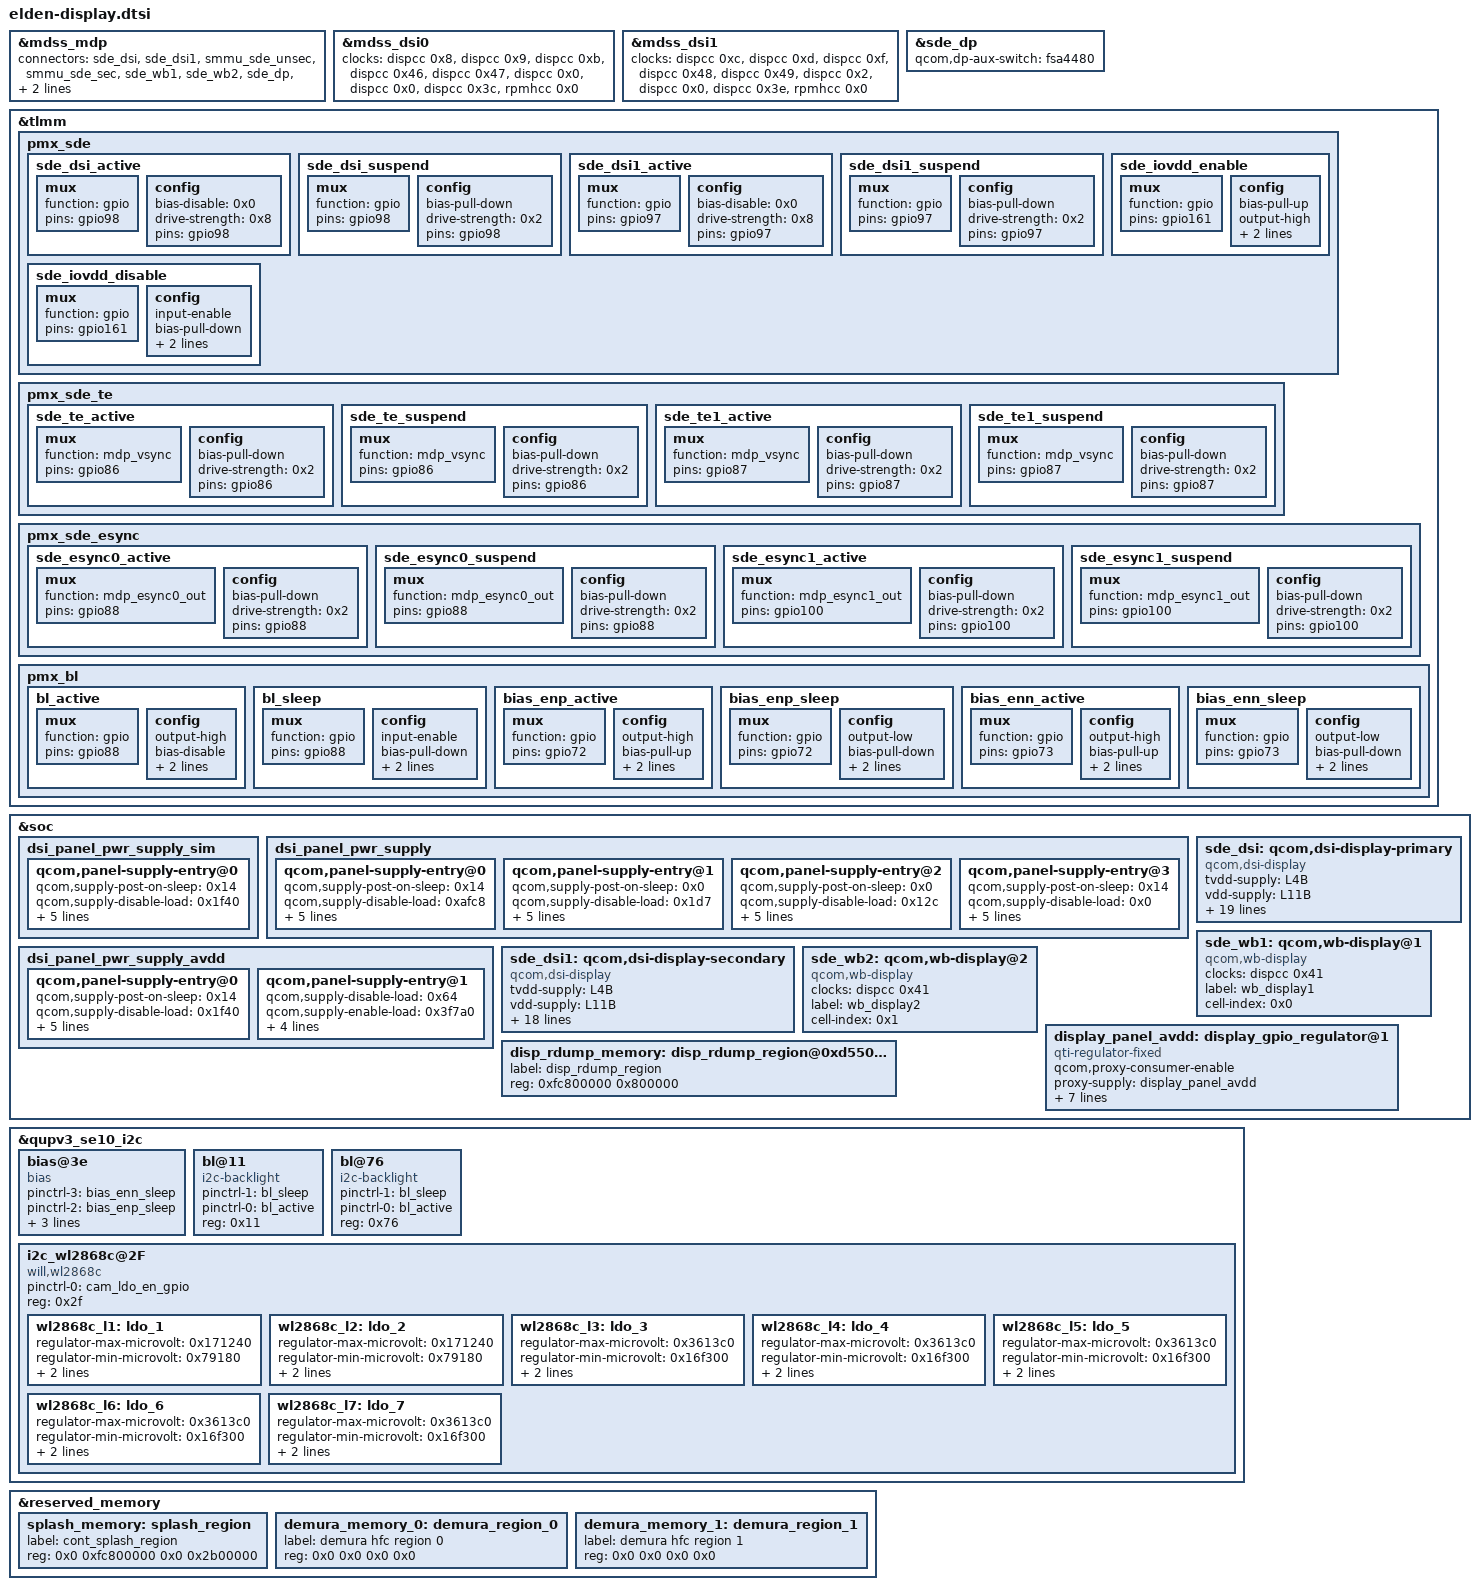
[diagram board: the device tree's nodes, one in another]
// SPDX-License-Identifier: GPL-2.0-only

#include "display/display/sun-sde.dtsi"

&mdss_mdp {
	connectors = <&sde_dsi &sde_dsi1 &smmu_sde_unsec &smmu_sde_sec &sde_wb1 &sde_wb2 &sde_dp &sde_cesta>;
	qcom,sde-max-bw-high-kbps = <0x1b2e020>;
	/delete-property/ qcom,sde-ctl-hyp-off;
	/delete-property/ qcom,sde-ctl-hyp-size;
};

&mdss_dsi0 {
	clocks = <&dispcc 0x8 &dispcc 0x9 &dispcc 0xb &dispcc 0x46 &dispcc 0x47 &dispcc 0x0 &dispcc 0x0 &dispcc 0x3c &rpmhcc 0x0>;
};

&mdss_dsi1 {
	clocks = <&dispcc 0xc &dispcc 0xd &dispcc 0xf &dispcc 0x48 &dispcc 0x49 &dispcc 0x2 &dispcc 0x0 &dispcc 0x3e &rpmhcc 0x0>;
};

&sde_dp {
	qcom,dp-aux-switch = <&fsa4480>;
};

#include "display/lenovo/elden-reference-panels.dtsi"
#include "display/lenovo/panel/dsi-panel-elden-nt36523-csot-3k-dsc-video.dtsi"
#include "display/lenovo/panel/dsi-panel-elden-nt36523-csot-dsc-video.dtsi"

&tlmm {

	pmx_sde: pmx_sde {

		sde_dsi_active: sde_dsi_active {

			mux {
				function = "gpio";
				pins = "gpio98";
			};

			config {
				bias-disable = <0x0>;
				drive-strength = <0x8>;
				pins = "gpio98";
			};
		};

		sde_dsi_suspend: sde_dsi_suspend {

			mux {
				function = "gpio";
				pins = "gpio98";
			};

			config {
				bias-pull-down;
				drive-strength = <0x2>;
				pins = "gpio98";
			};
		};

		sde_dsi1_active: sde_dsi1_active {

			mux {
				function = "gpio";
				pins = "gpio97";
			};

			config {
				bias-disable = <0x0>;
				drive-strength = <0x8>;
				pins = "gpio97";
			};
		};

		sde_dsi1_suspend: sde_dsi1_suspend {

			mux {
				function = "gpio";
				pins = "gpio97";
			};

			config {
				bias-pull-down;
				drive-strength = <0x2>;
				pins = "gpio97";
			};
		};

		sde_iovdd_enable: sde_iovdd_enable {

			mux {
				function = "gpio";
				pins = "gpio161";
			};

			config {
				bias-pull-up;
				output-high;
				drive-strength = <0x8>;
				pins = "gpio161";
			};
		};

		sde_iovdd_disable: sde_iovdd_disable {

			mux {
				function = "gpio";
				pins = "gpio161";
			};

			config {
				input-enable;
				bias-pull-down;
				drive-strength = <0x2>;
				pins = "gpio161";
			};
		};
	};

	pmx_sde_te: pmx_sde_te {

		sde_te_active: sde_te_active {

			mux {
				function = "mdp_vsync";
				pins = "gpio86";
			};

			config {
				bias-pull-down;
				drive-strength = <0x2>;
				pins = "gpio86";
			};
		};

		sde_te_suspend: sde_te_suspend {

			mux {
				function = "mdp_vsync";
				pins = "gpio86";
			};

			config {
				bias-pull-down;
				drive-strength = <0x2>;
				pins = "gpio86";
			};
		};

		sde_te1_active: sde_te1_active {

			mux {
				function = "mdp_vsync";
				pins = "gpio87";
			};

			config {
				bias-pull-down;
				drive-strength = <0x2>;
				pins = "gpio87";
			};
		};

		sde_te1_suspend: sde_te1_suspend {

			mux {
				function = "mdp_vsync";
				pins = "gpio87";
			};

			config {
				bias-pull-down;
				drive-strength = <0x2>;
				pins = "gpio87";
			};
		};
	};

	pmx_sde_esync: pmx_sde_esync {

		sde_esync0_active: sde_esync0_active {

			mux {
				function = "mdp_esync0_out";
				pins = "gpio88";
			};

			config {
				bias-pull-down;
				drive-strength = <0x2>;
				pins = "gpio88";
			};
		};

		sde_esync0_suspend: sde_esync0_suspend {

			mux {
				function = "mdp_esync0_out";
				pins = "gpio88";
			};

			config {
				bias-pull-down;
				drive-strength = <0x2>;
				pins = "gpio88";
			};
		};

		sde_esync1_active: sde_esync1_active {

			mux {
				function = "mdp_esync1_out";
				pins = "gpio100";
			};

			config {
				bias-pull-down;
				drive-strength = <0x2>;
				pins = "gpio100";
			};
		};

		sde_esync1_suspend: sde_esync1_suspend {

			mux {
				function = "mdp_esync1_out";
				pins = "gpio100";
			};

			config {
				bias-pull-down;
				drive-strength = <0x2>;
				pins = "gpio100";
			};
		};
	};
};

&soc {

	dsi_panel_pwr_supply_sim: dsi_panel_pwr_supply_sim {
		#size-cells = <0x0>;
		#address-cells = <0x1>;

		qcom,panel-supply-entry@0 {
			qcom,supply-post-on-sleep = <0x14>;
			qcom,supply-disable-load = <0x1f40>;
			qcom,supply-enable-load = <0x35b60>;
			qcom,supply-max-voltage = <0x1b7740>;
			qcom,supply-min-voltage = <0x1b7740>;
			qcom,supply-name = "dummy";
			reg = <0x0>;
		};
	};

	dsi_panel_pwr_supply: dsi_panel_pwr_supply {
		#size-cells = <0x0>;
		#address-cells = <0x1>;

		qcom,panel-supply-entry@0 {
			qcom,supply-post-on-sleep = <0x14>;
			qcom,supply-disable-load = <0xafc8>;
			qcom,supply-enable-load = <0x25990>;
			qcom,supply-max-voltage = <0x1b7740>;
			qcom,supply-min-voltage = <0x1b7740>;
			qcom,supply-name = "vddio";
			reg = <0x0>;
		};

		qcom,panel-supply-entry@1 {
			qcom,supply-post-on-sleep = <0x0>;
			qcom,supply-disable-load = <0x1d7>;
			qcom,supply-enable-load = <0x35b60>;
			qcom,supply-max-voltage = <0x10c8e0>;
			qcom,supply-min-voltage = <0xf4240>;
			qcom,supply-name = "vdd";
			reg = <0x1>;
		};

		qcom,panel-supply-entry@2 {
			qcom,supply-post-on-sleep = <0x0>;
			qcom,supply-disable-load = <0x12c>;
			qcom,supply-enable-load = <0x2710>;
			qcom,supply-max-voltage = <0x2dc6c0>;
			qcom,supply-min-voltage = <0x2dc6c0>;
			qcom,supply-name = "vci";
			reg = <0x2>;
		};

		qcom,panel-supply-entry@3 {
			qcom,supply-post-on-sleep = <0x14>;
			qcom,supply-disable-load = <0x0>;
			qcom,supply-enable-load = <0x0>;
			qcom,supply-max-voltage = <0x1b7740>;
			qcom,supply-min-voltage = <0x1b7740>;
			qcom,supply-name = "tvdd";
			reg = <0x3>;
		};
	};

	dsi_panel_pwr_supply_avdd: dsi_panel_pwr_supply_avdd {
		#size-cells = <0x0>;
		#address-cells = <0x1>;

		qcom,panel-supply-entry@0 {
			qcom,supply-post-on-sleep = <0x14>;
			qcom,supply-disable-load = <0x1f40>;
			qcom,supply-enable-load = <0x35b60>;
			qcom,supply-max-voltage = <0x1b7740>;
			qcom,supply-min-voltage = <0x1b7740>;
			qcom,supply-name = "vddio";
			reg = <0x0>;
		};

		qcom,panel-supply-entry@1 {
			qcom,supply-disable-load = <0x64>;
			qcom,supply-enable-load = <0x3f7a0>;
			qcom,supply-max-voltage = <0x5b8d80>;
			qcom,supply-min-voltage = <0x4630c0>;
			qcom,supply-name = "avdd";
			reg = <0x1>;
		};
	};

	sde_dsi: qcom,dsi-display-primary {
		tvdd-supply = <&L4B>;
		vdd-supply = <&L11B>;
		vci-supply = <&L13B>;
		vddio-supply = <&L12B>;
		clock-names = "pll_byte_clk0", "pll_dsi_clk0", "pll_byte_clk1", "pll_dsi_clk1", "mdp_core_clk", "esync_clk_rcg";
		clocks = <&mdss_dsi_phy0 0x0 &mdss_dsi_phy0 0x1 &mdss_dsi_phy1 0x0 &mdss_dsi_phy1 0x1 &dispcc 0x41 &dispcc 0x1>;
		qcom,demura-panel-id = <0x122e700 0x471>;
		qcom,dsi-default-panel = <&elden_nt36523_csot_3k_dsc_vid>;
		qcom,mdp = <&mdss_mdp>;
		qcom,panel-te-source = <0x0>;
		qcom,platform-te-gpio = <&tlmm 0x56 0x0>;
		pinctrl-4 = <&sde_iovdd_disable>;
		pinctrl-3 = <&sde_iovdd_enable>;
		pinctrl-2 = <&sde_dsi_suspend &sde_te_suspend>;
		pinctrl-1 = <&sde_dsi_active &sde_te_active>;
		pinctrl-0 = <&sde_dsi_active &sde_te_active>;
		pinctrl-names = "panel_active", "panel_active_with_esync", "panel_suspend", "iovdd_enable", "iovdd_disable";
		qcom,dsi-phy = <&mdss_dsi_phy0 &mdss_dsi_phy1>;
		qcom,dsi-ctrl = <&mdss_dsi0 &mdss_dsi1>;
		label = "primary";
		compatible = "qcom,dsi-display";
	};

	sde_dsi1: qcom,dsi-display-secondary {
		tvdd-supply = <&L4B>;
		vdd-supply = <&L11B>;
		vci-supply = <&L13B>;
		vddio-supply = <&L12B>;
		clock-names = "pll_byte_clk0", "pll_dsi_clk0", "pll_byte_clk1", "pll_dsi_clk1", "mdp_core_clk", "esync_clk_rcg";
		clocks = <&mdss_dsi_phy0 0x0 &mdss_dsi_phy0 0x1 &mdss_dsi_phy1 0x0 &mdss_dsi_phy1 0x1 &dispcc 0x41 &dispcc 0x3>;
		qcom,demura-panel-id = <0x0 0x0>;
		qcom,mdp = <&mdss_mdp>;
		qcom,panel-te-source = <0x1>;
		qcom,platform-te-gpio = <&tlmm 0x57 0x0>;
		pinctrl-2 = <&sde_dsi1_suspend &sde_te1_suspend &sde_esync1_suspend>;
		pinctrl-1 = <&sde_dsi1_active &sde_te1_active &sde_esync1_active>;
		pinctrl-0 = <&sde_dsi1_active &sde_te1_active &sde_esync1_suspend>;
		pinctrl-names = "panel_active", "panel_active_with_esync", "panel_suspend";
		qcom,dsi-phy = <&mdss_dsi_phy0 &mdss_dsi_phy1>;
		qcom,dsi-ctrl = <&mdss_dsi0 &mdss_dsi1>;
		label = "secondary";
		compatible = "qcom,dsi-display";
	};
};

&tlmm {

	pmx_bl: pmx_bl {

		bl_active: bl_active {

			mux {
				function = "gpio";
				pins = "gpio88";
			};

			config {
				output-high;
				bias-disable;
				drive-strength = <0x8>;
				pins = "gpio88";
			};
		};

		bl_sleep: bl_sleep {

			mux {
				function = "gpio";
				pins = "gpio88";
			};

			config {
				input-enable;
				bias-pull-down;
				drive-strength = <0x2>;
				pins = "gpio88";
			};
		};

		bias_enp_active: bias_enp_active {

			mux {
				function = "gpio";
				pins = "gpio72";
			};

			config {
				output-high;
				bias-pull-up;
				drive-strength = <0x10>;
				pins = "gpio72";
			};
		};

		bias_enp_sleep: bias_enp_sleep {

			mux {
				function = "gpio";
				pins = "gpio72";
			};

			config {
				output-low;
				bias-pull-down;
				drive-strength = <0x2>;
				pins = "gpio72";
			};
		};

		bias_enn_active: bias_enn_active {

			mux {
				function = "gpio";
				pins = "gpio73";
			};

			config {
				output-high;
				bias-pull-up;
				drive-strength = <0x10>;
				pins = "gpio73";
			};
		};

		bias_enn_sleep: bias_enn_sleep {

			mux {
				function = "gpio";
				pins = "gpio73";
			};

			config {
				output-low;
				bias-pull-down;
				drive-strength = <0x2>;
				pins = "gpio73";
			};
		};
	};
};

&qupv3_se10_i2c {
	status = "okay";

	bias@3e {
		pinctrl-3 = <&bias_enn_sleep>;
		pinctrl-2 = <&bias_enp_sleep>;
		pinctrl-1 = <&bias_enn_active>;
		pinctrl-0 = <&bias_enp_active>;
		pinctrl-names = "enp_active", "enn_active", "enp_sleep", "enn_sleep";
		reg = <0x3e>;
		compatible = "bias";
	};

	bl@11 {
		pinctrl-1 = <&bl_sleep>;
		pinctrl-0 = <&bl_active>;
		pinctrl-names = "default", "sleep";
		reg = <0x11>;
		compatible = "i2c-backlight";
	};

	bl@76 {
		pinctrl-1 = <&bl_sleep>;
		pinctrl-0 = <&bl_active>;
		pinctrl-names = "default", "sleep";
		reg = <0x76>;
		compatible = "i2c-backlight";
	};
};

&soc {

	sde_wb1: qcom,wb-display@1 {
		clock-names = "mdp_core_clk";
		clocks = <&dispcc 0x41>;
		label = "wb_display1";
		cell-index = <0x0>;
		compatible = "qcom,wb-display";
	};

	sde_wb2: qcom,wb-display@2 {
		clock-names = "mdp_core_clk";
		clocks = <&dispcc 0x41>;
		label = "wb_display2";
		cell-index = <0x1>;
		compatible = "qcom,wb-display";
	};

	display_panel_avdd: display_gpio_regulator@1 {
		pinctrl-names = "default";
		qcom,proxy-consumer-enable;
		proxy-supply = <&display_panel_avdd>;
		regulator-boot-on;
		enable-active-high;
		gpio = <&pm8550_gpios 0xb 0x0>;
		regulator-enable-ramp-delay = <0xe9>;
		regulator-max-microvolt = <0x53ec60>;
		regulator-min-microvolt = <0x53ec60>;
		regulator-name = "display_panel_avdd";
		compatible = "qti-regulator-fixed";
	};

	disp_rdump_memory: disp_rdump_region@0xd5500000 {
		label = "disp_rdump_region";
		reg = <0xfc800000 0x800000>;
	};
};

&reserved_memory {

	splash_memory: splash_region {
		label = "cont_splash_region";
		reg = <0x0 0xfc800000 0x0 0x2b00000>;
	};

	demura_memory_0: demura_region_0 {
		label = "demura hfc region 0";
		reg = <0x0 0x0 0x0 0x0>;
	};

	demura_memory_1: demura_region_1 {
		label = "demura hfc region 1";
		reg = <0x0 0x0 0x0 0x0>;
	};
};

&qupv3_se10_i2c {
	status = "okay";
	#size-cells = <0x0>;
	#address-cells = <0x1>;

	i2c_wl2868c@2F {
		pinctrl-0 = <&cam_ldo_en_gpio>;
		pinctrl-names = "default";
		reg = <0x2f>;
		compatible = "will,wl2868c";

		wl2868c_l1: ldo_1 {
			regulator-max-microvolt = <0x171240>;
			regulator-min-microvolt = <0x79180>;
			regulator-name = "ldo_1";
			ldo-channel = <0x0>;
		};

		wl2868c_l2: ldo_2 {
			regulator-max-microvolt = <0x171240>;
			regulator-min-microvolt = <0x79180>;
			regulator-name = "ldo_2";
			ldo-channel = <0x1>;
		};

		wl2868c_l3: ldo_3 {
			regulator-max-microvolt = <0x3613c0>;
			regulator-min-microvolt = <0x16f300>;
			regulator-name = "ldo_3";
			ldo-channel = <0x2>;
		};

		wl2868c_l4: ldo_4 {
			regulator-max-microvolt = <0x3613c0>;
			regulator-min-microvolt = <0x16f300>;
			regulator-name = "ldo_4";
			ldo-channel = <0x3>;
		};

		wl2868c_l5: ldo_5 {
			regulator-max-microvolt = <0x3613c0>;
			regulator-min-microvolt = <0x16f300>;
			regulator-name = "ldo_5";
			ldo-channel = <0x4>;
		};

		wl2868c_l6: ldo_6 {
			regulator-max-microvolt = <0x3613c0>;
			regulator-min-microvolt = <0x16f300>;
			regulator-name = "ldo_6";
			ldo-channel = <0x5>;
		};

		wl2868c_l7: ldo_7 {
			regulator-max-microvolt = <0x3613c0>;
			regulator-min-microvolt = <0x16f300>;
			regulator-name = "ldo_7";
			ldo-channel = <0x6>;
		};
	};
};
